# CY8C5888LTI_LP097 register map
File version: 0.1
Registers are 8-bit, read-write, no defined reset value unless marked. A register's access mark holds for its fields unless they carry their own. Offsets are from the block's base; [hi:lo] are bit positions; 'fields as' and 'values as' point back to an identical list.

## PWM_green
Base 0x00000000
0x40006424 PWM_green_COMPARE_Reg 16-bit — UDB.D0 - Assigned Compare Value
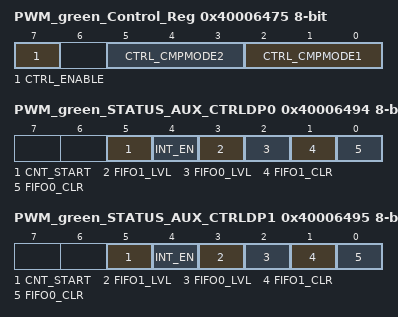
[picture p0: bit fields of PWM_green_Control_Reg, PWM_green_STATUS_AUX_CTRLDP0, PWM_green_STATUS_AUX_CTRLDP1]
0x40006475 PWM_green_Control_Reg — UDB Control Register - Assigned Control Register Value
  [7] CTRL_ENABLE — Enable the PWM
  [5:3] CTRL_CMPMODE2 — Compare mode 2
  [2:0] CTRL_CMPMODE1 — Compare mode 1
0x40006494 PWM_green_STATUS_AUX_CTRLDP0 — UDB Auxilliary Control Register
  [5] CNT_START — FIFO0 clear
    0=E_CNT_START0 (Disable counter); 1=E_CNT_START1 (Enable counter)
  [4] INT_EN
    0=E_INT_EN0 (Interrupt disabled); 1=E_INT_EN1 (Interrupt enabled)
  [3] FIFO1_LVL — FIFO level
    0=E_FIFO_LVL_0 (FIFO LVL: input mode: FIFO not full; output mode: FIFO not empty); 1=E_FIFO_LVL_1 (FIFO LVL: input mode: FIFO at least 1/2 empty; output mode: FIFO at least 1/2 full)
  [2] FIFO0_LVL — FIFO level
    values as FIFO1_LVL
  [1] FIFO1_CLR — FIFO1 clear
    0=E_FIFO_CLR_0 (Normal FIFO operation); 1=E_FIFO_CLR_1 (Clear FIFO state)
  [0] FIFO0_CLR — FIFO0 clear
    values as FIFO1_CLR
0x40006495 PWM_green_STATUS_AUX_CTRLDP1 — UDB Auxilliary Control Register
  fields as PWM_green_STATUS_AUX_CTRLDP0

## PWM_yellow
Base 0x00000000
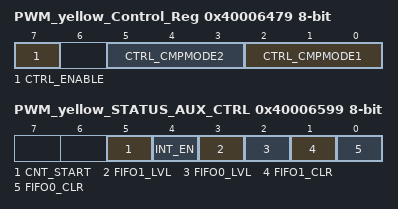
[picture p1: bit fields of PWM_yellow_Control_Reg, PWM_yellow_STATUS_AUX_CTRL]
0x40006479 PWM_yellow_Control_Reg — UDB Control Register - Assigned Control Register Value
  [7] CTRL_ENABLE — Enable the PWM
  [5:3] CTRL_CMPMODE2 — Compare mode 2
  [2:0] CTRL_CMPMODE1 — Compare mode 1
0x40006529 PWM_yellow_COMPARE_Reg_ — UDB.D0 - Assigned Compare Value
0x40006599 PWM_yellow_STATUS_AUX_CTRL — UDB Auxilliary Control Register
  [5] CNT_START — FIFO0 clear
    0=E_CNT_START0 (Disable counter); 1=E_CNT_START1 (Enable counter)
  [4] INT_EN
    0=E_INT_EN0 (Interrupt disabled); 1=E_INT_EN1 (Interrupt enabled)
  [3] FIFO1_LVL — FIFO level
    0=E_FIFO_LVL_0 (FIFO LVL: input mode: FIFO not full; output mode: FIFO not empty); 1=E_FIFO_LVL_1 (FIFO LVL: input mode: FIFO at least 1/2 empty; output mode: FIFO at least 1/2 full)
  [2] FIFO0_LVL — FIFO level
    values as FIFO1_LVL
  [1] FIFO1_CLR — FIFO1 clear
    0=E_FIFO_CLR_0 (Normal FIFO operation); 1=E_FIFO_CLR_1 (Clear FIFO state)
  [0] FIFO0_CLR — FIFO0 clear
    values as FIFO1_CLR

## PWM_red
Base 0x00000000
0x40006422 PWM_red_COMPARE_Reg_ — UDB.D0 - Assigned Compare Value
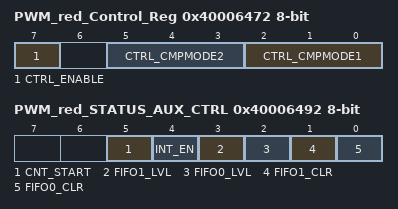
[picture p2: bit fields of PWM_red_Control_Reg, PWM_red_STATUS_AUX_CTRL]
0x40006472 PWM_red_Control_Reg — UDB Control Register - Assigned Control Register Value
  [7] CTRL_ENABLE — Enable the PWM
  [5:3] CTRL_CMPMODE2 — Compare mode 2
  [2:0] CTRL_CMPMODE1 — Compare mode 1
0x40006492 PWM_red_STATUS_AUX_CTRL — UDB Auxilliary Control Register
  [5] CNT_START — FIFO0 clear
    0=E_CNT_START0 (Disable counter); 1=E_CNT_START1 (Enable counter)
  [4] INT_EN
    0=E_INT_EN0 (Interrupt disabled); 1=E_INT_EN1 (Interrupt enabled)
  [3] FIFO1_LVL — FIFO level
    0=E_FIFO_LVL_0 (FIFO LVL: input mode: FIFO not full; output mode: FIFO not empty); 1=E_FIFO_LVL_1 (FIFO LVL: input mode: FIFO at least 1/2 empty; output mode: FIFO at least 1/2 full)
  [2] FIFO0_LVL — FIFO level
    values as FIFO1_LVL
  [1] FIFO1_CLR — FIFO1 clear
    0=E_FIFO_CLR_0 (Normal FIFO operation); 1=E_FIFO_CLR_1 (Clear FIFO state)
  [0] FIFO0_CLR — FIFO0 clear
    values as FIFO1_CLR

## Buttons_Status
Base 0x00000000
0x40006462 Buttons_Status_STATUS_REG
0x40006482 Buttons_Status_MASK_REG
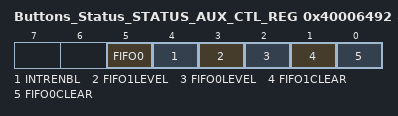
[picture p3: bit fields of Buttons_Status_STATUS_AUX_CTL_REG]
0x40006492 Buttons_Status_STATUS_AUX_CTL_REG
  [5] FIFO0 — FIFO0 clear
    1=ENABLED (Enable counter); 0=DISABLED (Disable counter)
  [4] INTRENBL — Enables or disables the Interrupt
    1=ENABLED (Interrupt enabled); 0=DISABLED (Interrupt disabled)
  [3] FIFO1LEVEL — FIFO level
    1=ENABLED (FIFO LVL: input mode: FIFO at least 1/2 empty; output mode: FIFO at least 1/2 full); 0=DISABLED (FIFO LVL: input mode: FIFO not full; output mode: FIFO not empty)
  [2] FIFO0LEVEL — FIFO level
    values as FIFO1LEVEL
  [1] FIFO1CLEAR — FIFO clear
    1=ENABLED (Clear FIFO state); 0=DISABLED (Normal FIFO operation)
  [0] FIFO0CLEAR — FIFO clear
    values as FIFO1CLEAR

## SEVEN_reg
Base 0x00000000
0x40006579 SEVEN_reg_CONTROL_REG
